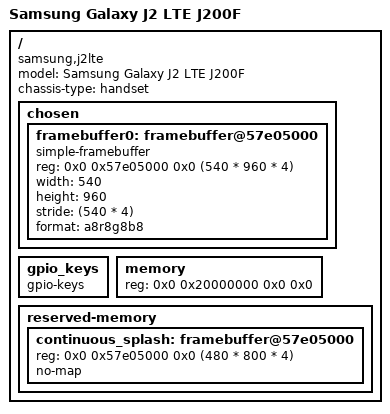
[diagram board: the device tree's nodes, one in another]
// SPDX-License-Identifier: BSD-3-Clause
/*
 * Samsung's Galaxy Xcover 3 Value Edition Device Tree
 *
 * Copyright (c) 2024, Ivaylo Ivanov <ivo.ivanov.ivanov1@gmail.com>
 */
/dts-v1/;

#include <dt-bindings/gpio/gpio.h>
#include <dt-bindings/input/input.h>
#include "exynos3475.dtsi"

/ {
	model = "Samsung Galaxy J2 LTE J200F";
	compatible = "samsung,j2lte", "samsung,exynos3475";
	chassis-type = "handset";

	chosen {
		#address-cells = <2>;
		#size-cells = <2>;
		ranges;

		framebuffer0: framebuffer@57e05000 {
			status= "okay";
			compatible = "simple-framebuffer";
			reg = <0x0 0x57e05000 0x0 (540 * 960 * 4)>;
			width = <540>;
			height = <960>;
			stride = <(540 * 4)>;
			format = "a8r8g8b8";
		};
	};

	gpio_keys {
		compatible = "gpio-keys";
		#address-cells = <1>;
		#size-cells = <0>;

	};

	memory {
		device_type = "memory";
		/* We expect the bootloader to fill in the reg */
		reg = <0x0 0x20000000 0x0 0x0>;
	};

	reserved-memory {
		#address-cells = <2>;
		#size-cells = <2>;
		ranges;

		continuous_splash: framebuffer@57e05000 {
			reg = <0x0 0x57e05000 0x0 (480 * 800 * 4)>;
			no-map;
		};
	};
};
